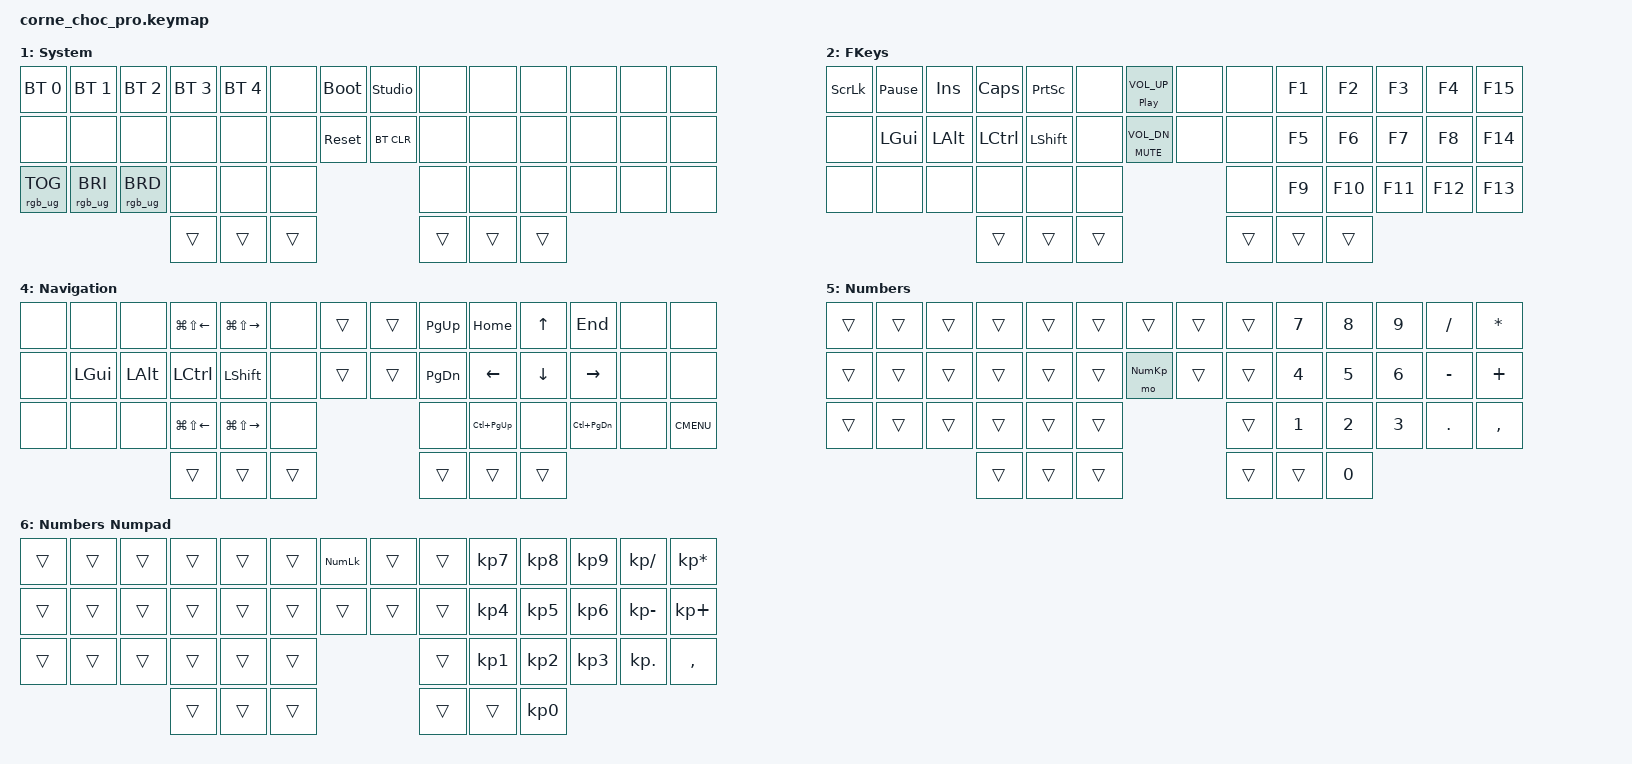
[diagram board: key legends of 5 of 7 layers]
/*
 * Copyright (c) 2020 The ZMK Contributors
 *
 * SPDX-License-Identifier: MIT
 */

#include <behaviors.dtsi>
#include <dt-bindings/zmk/keys.h>
#include <dt-bindings/zmk/bt.h>
#include <dt-bindings/zmk/rgb.h>

/ {
    chosen {
        zmk,physical-layout = &default_layout;
    };
};


/* Layers */
#define Base     0
#define Sys      1
#define FKeys    2
#define NavNum   3
#define Nav      4
#define Num      5
#define NumKp    6

#include "incl/corne_labels.h"
#include "incl/combos_lr.dtsi"
#include "incl/morphs.dtsi"
#include "incl/behaviors.dtsi"

#define __         &trans
#define xx         &none
#define PAUSEB     &kp PAUSE_BREAK

#define VOLDN_MUT  &mttl C_MUTE       C_VOL_DN
#define VOLUP_PLAY &mttl C_PLAY_PAUSE C_VOL_UP
#define BSPC_W     &mtts LC(BSPC)     BSPC
#define DEL_W      &mtts LC(DEL)      DEL

#define DESK_LEFT  &kp LG(LS(LEFT))
#define DESK_RIGHT &kp LG(LS(RIGHT))
#define DESK_PREV  &kp LG(LS(LEFT))
#define DESK_NEXT  &kp LG(LS(RIGHT))

/ {
    keymap {
        compatible = "zmk,keymap";


base_layer {  display-name = "Base";  bindings = <
// ╭──────────┬────────────┬────────────┬────────────┬─────────────┬──────────┬───────────╮╭───────────┬──────────┬──────────────┬────────────┬────────────┬────────────┬──────────╮
    &kp GRAVE  &kp B        &kp Y        &kp O        &kp U         &kp SQT    VOLUP_PLAY   BSPC_W      &min_plu   &kp L          &kp D        &kp W        &kp V        &kp Z
// ├──────────┼────────────┼────────────┼────────────┼─────────────┼──────────┼───────────┤├───────────┼──────────┼──────────────┼────────────┼────────────┼────────────┼──────────┤
    &eq_ex     HML(C,           I,           E,           A)        &com_sem   VOLDN_MUT    DEL_W       &dot_col   HMR(H,             T,           S,           N)       &kp Q
// ├──────────┼────────────┼────────────┼────────────┼─────────────┼──────────┼───────────╯╰───────────┼──────────┼──────────────┼────────────┼────────────┼────────────┼──────────┤
    xx         &kp G        &kp X        &kp J        &kp K         &q_ex                               &sl_star   &kp R          &kp M        &kp F        &kp P        &kp K_CMENU
// ╰──────────┴────────────┴────────────┼────────────┼─────────────┼──────────┤                        ├──────────┼──────────────┼────────────┼────────────┴────────────┴──────────╯
                                         &lcw Sys 0   &lt Num ESC   &kp SPACE                           &kp SPACE  &lt Nav TAB    &lcw FKeys 0
//                                      ╰────────────┴─────────────┴──────────╯                        ╰──────────┴──────────────┴────────────╯
>; };

sys_layer {  display-name = "System";  bindings = <
// ╭───────────────┬───────────────┬───────────────┬────────────┬─────────────┬──────────┬──────────╮╭──────────────┬─────────────┬─────────────┬─────────────┬─────────────┬────────────┬────────────╮
    &bt BT_SEL 0    &bt BT_SEL 1    &bt BT_SEL 2    &bt BT_SEL 3  &bt BT_SEL 4 xx         &bootloader &studio_unlock xx            xx            xx            xx            xx           xx   
// ├───────────────┼───────────────┼───────────────┼────────────┼─────────────┼──────────┼──────────┤├──────────────┼─────────────┼─────────────┼─────────────┼─────────────┼────────────┼────────────┤
    xx              xx              xx              xx           xx            xx         &sys_reset  &bt BT_CLR     xx            xx            xx            xx            xx           xx   
// ├───────────────┼───────────────┼───────────────┼────────────┼─────────────┼──────────┼──────────╯╰──────────────┼─────────────┼─────────────┼─────────────┼─────────────┼────────────┼────────────┤
    &rgb_ug RGB_TOG &rgb_ug RGB_BRI &rgb_ug RGB_BRD xx           xx            xx                                    xx            xx            xx            xx            xx           xx   
// ╰───────────────┴───────────────┴───────────────┼────────────┼─────────────┼──────────┤                          ├─────────────┴─────────────┴─────────────┴─────────────┴────────────┴────────────╯
                                                    __           __            __                                    __            __            __    
//                                                 ╰────────────┴─────────────┴──────────╯                          ╰─────────────┴─────────────┴─────────────╯
>; };

fkeys_layer {  display-name = "FKeys";  bindings = <
// ╭──────────┬──────────┬───────────┬──────────┬──────────┬──────────┬───────────╮╭──────────┬──────────┬──────────┬──────────┬──────────┬──────────┬──────────╮
    &kp SLCK   PAUSEB     &kp INS     &kp CAPS   &kp PSCRN  xx         VOLUP_PLAY   xx         xx         &kp F1     &kp F2     &kp F3     &kp F4     &kp F15
// ├──────────┼──────────┼───────────┼──────────┼──────────┼──────────┼───────────┤├──────────┼──────────┼──────────┼──────────┼──────────┼──────────┼──────────┤
    xx         &kp LGUI   &kp LALT    &kp LCTRL  &kp LSHFT  xx         VOLDN_MUT    xx         xx         &kp F5     &kp F6     &kp F7     &kp F8     &kp F14
// ├──────────┼──────────┼───────────┼──────────┼──────────┼──────────┼───────────╯╰──────────┼──────────┼──────────┼──────────┼──────────┼──────────┼──────────┤
    xx         xx         xx          xx         xx         xx                                 xx         &kp F9     &kp F10    &kp F11    &kp F12    &kp F13
// ╰──────────┴──────────┴───────────┼──────────┼──────────┼──────────┤                       ├──────────┼──────────┼──────────┼──────────┴──────────┴──────────╯
                                      __         __         __                                 __         __         __    
//                                   ╰──────────┴──────────┴──────────╯                       ╰──────────┴──────────┴──────────╯
>; };

navnum_layer {  display-name = "Nav-Num";  bindings = <
// ╭──────────┬───────────┬────────────┬───────────┬──────────────┬─────────┬──────────╮╭──────────┬──────────┬──────────┬──────────┬──────────┬───────────┬──────────╮
    &kp N0     &kp N1      &kp N2       &kp N3      &kp N4         &kp N5    __          __         __         &kp N6     &kp N7     &kp N8     &kp N9      &kp N0
// ├──────────┼───────────┼────────────┼───────────┼──────────────┼─────────┼──────────┤├──────────┼──────────┼──────────┼──────────┼──────────┼───────────┼──────────┤
    __         __          __           __          &hml LSHFT N5  __        __          __         &kp LEFT   HMR(UP,    DOWN,      RIGHT,     RIGHT)      xx   
// ├──────────┼───────────┼────────────┼───────────┼──────────────┼─────────┼──────────╯╰──────────┼──────────┼──────────┼──────────┼──────────┼───────────┼──────────┤
    __         DESK_LEFT   DESK_RIGHT   DESK_PREV   DESK_NEXT      __                               &kp HOME   &kp PG_UP  &kp PG_DN  &kp END    xx          __
// ╰──────────┴───────────┴────────────┼───────────┼──────────────┼─────────┤                      ├──────────┼──────────┼──────────┼──────────┴───────────┴──────────╯
                                        __          __             __                               __         __         __    
//                                     ╰───────────┴──────────────┴─────────╯                      ╰──────────┴──────────┴──────────╯
>; };

/* navnum_lr_layer {  display-name = "NavNum_LR";  bindings = <
// ╭──────────┬──────────┬──────────────┬───────────────┬────────────────┬─────────────┬──────────╮╭──────────┬──────────┬────────────────┬────────────────┬───────────────┬──────────┬──────────╮
    xx         xx         &kp HOME       &kp UP          &kp END          &kp PG_UP     xx          __         __         &kp KP_N7        &kp KP_N8        &kp KP_N9       xx         xx   
// ├──────────┼──────────┼──────────────┼───────────────┼────────────────┼─────────────┼──────────┤├──────────┼──────────┼────────────────┼────────────────┼───────────────┼──────────┼──────────┤
    xx         xx         &hml LALT LEFT &hml LCTRL DOWN &hml LSHFT RIGHT &kp PG_DN     xx          __         __         &hmr RSHFT KP_N4 &hmr RCTRL KP_N5 &hmr RALT KP_N6 xx         xx   
// ├──────────┼──────────┼──────────────┼───────────────┼────────────────┼─────────────┼──────────╯╰──────────┼──────────┼────────────────┼────────────────┼───────────────┼──────────┼──────────┤
    xx         xx         xx             xx              xx               xx                                   __         &kp KP_N1        &kp KP_N2        &kp KP_N3       xx         xx   
// ╰──────────┴──────────┴──────────────┼───────────────┼────────────────┼─────────────┤                      ├──────────┼────────────────┼────────────────┼───────────────┴──────────┴──────────╯
                                         __              __               __                                   __         __               &kp KP_N0
//                                      ╰───────────────┴────────────────┴─────────────╯                      ╰──────────┴────────────────┴────────────────╯
>; }; */

nav_layer {  display-name = "Navigation";  bindings = <
// ╭──────────┬──────────┬──────────┬──────────┬────────────┬────────────┬──────────╮╭──────────┬──────────┬─────────────┬─────────────┬─────────────┬──────────┬──────────╮
    xx         xx         xx         DESK_LEFT  DESK_RIGHT   xx           __          __         &kp PG_UP  &kp HOME      &kp UP        &kp END       xx         xx   
// ├──────────┼──────────┼──────────┼──────────┼────────────┼────────────┼──────────┤├──────────┼──────────┼─────────────┼─────────────┼─────────────┼──────────┼──────────┤
    xx         &kp LGUI   &kp LALT   &kp LCTRL  &kp LSHFT    xx           __          __         &kp PG_DN  &kp LEFT      &kp DOWN      &kp RIGHT     xx         xx   
// ├──────────┼──────────┼──────────┼──────────┼────────────┼────────────┼──────────╯╰──────────┼──────────┼─────────────┼─────────────┼─────────────┼──────────┼──────────┤
    xx         xx         xx         DESK_PREV  DESK_NEXT    xx                                  xx         &kp LC(PG_UP) xx            &kp LC(PG_DN) xx         &kp K_CMENU   
// ╰──────────┴──────────┴──────────┼──────────┼────────────┼────────────┤                      ├──────────┼─────────────┼─────────────┼─────────────┴──────────┴──────────╯
                                     __         __           __                                  __         __            __    
//                                  ╰──────────┴────────────┴────────────╯                      ╰──────────┴─────────────┴─────────────╯
>; };

num_layer {  display-name = "Numbers";  bindings = <
// ╭──────────┬──────────┬──────────┬──────────┬──────────┬──────────┬──────────╮╭──────────┬──────────┬──────────┬──────────┬──────────┬──────────┬──────────╮
    __         __         __         __         __         __         __          __         __         &kp N7     &kp N8     &kp N9     &kp SLASH  &kp STAR   
// ├──────────┼──────────┼──────────┼──────────┼──────────┼──────────┼──────────┤├──────────┼──────────┼──────────┼──────────┼──────────┼──────────┼──────────┤
    __         __         __         __         __         __         &mo NumKp   __         __         &kp N4     &kp N5     &kp N6     &kp MINUS  &kp PLUS   
//  __         &kp LGUI   &kp LALT   &kp LCTRL  &kp LSHFT  __         &mo NumKp   __         __         &kp N4     &kp N5     &kp N6     &kp MINUS  &kp PLUS   
// ├──────────┼──────────┼──────────┼──────────┼──────────┼──────────┼──────────╯╰──────────┼──────────┼──────────┼──────────┼──────────┼──────────┼──────────┤
    __         __         __         __         __         __                                __         &kp N1     &kp N2     &kp N3     &kp DOT    &kp COMMA
// ╰──────────┴──────────┴──────────┼──────────┼──────────┼──────────┤                      ├──────────┼──────────┼──────────┼──────────┴──────────┴──────────╯
                                     __         __         __                                __         __         &kp N0  
//                                  ╰──────────┴──────────┴──────────╯                      ╰──────────┴──────────┴──────────╯
>; };

numkp_layer {  display-name = "Numbers Numpad";  bindings = <
// ╭──────────┬──────────┬──────────┬──────────┬──────────┬──────────┬──────────╮╭──────────┬──────────┬──────────┬──────────┬──────────┬────────────┬───────────────╮
    __         __         __         __         __         __         &kp KP_NLCK __         __         &kp KP_N7  &kp KP_N8  &kp KP_N9  &kp KP_SLASH &kp KP_MULTIPLY   
// ├──────────┼──────────┼──────────┼──────────┼──────────┼──────────┼──────────┤├──────────┼──────────┼──────────┼──────────┼──────────┼────────────┼───────────────┤
    __         __         __         __         __         __         __          __         __         &kp KP_N4  &kp KP_N5  &kp KP_N6  &kp KP_MINUS &kp KP_PLUS   
//  __         &kp LGUI   &kp LALT   &kp LCTRL  &kp LSHFT  __         __          __         __         &kp KP_N4  &kp KP_N5  &kp KP_N6  &kp KP_MINUS &kp KP_PLUS   
// ├──────────┼──────────┼──────────┼──────────┼──────────┼──────────┼──────────╯╰──────────┼──────────┼──────────┼──────────┼──────────┼────────────┼───────────────┤
    __         __         __         __         __         __                                __         &kp KP_N1  &kp KP_N2  &kp KP_N3  &kp KP_DOT   &kp COMMA
// ╰──────────┴──────────┴──────────┼──────────┼──────────┼──────────┤                      ├──────────┼──────────┼──────────┼──────────┴────────────┴───────────────╯
                                     __         __         __                                __         __         &kp KP_N0  
//                                  ╰──────────┴──────────┴──────────╯                      ╰──────────┴──────────┴──────────╯
>; };

/*
none_layer {  display-name = "none";  bindings = <
// ╭──────────┬──────────┬──────────┬──────────┬──────────┬──────────┬──────────╮╭──────────┬──────────┬──────────┬──────────┬──────────┬──────────┬──────────╮
    &none      &none      &none      &none      &none      &none      &none       &none      &none      &none      &none      &none      &none      &none
// ├──────────┼──────────┼──────────┼──────────┼──────────┼──────────┼──────────┤├──────────┼──────────┼──────────┼──────────┼──────────┼──────────┼──────────┤
    &none      &none      &none      &none      &none      &none      &none       &none      &none      &none      &none      &none      &none      &none
// ├──────────┼──────────┼──────────┼──────────┼──────────┼──────────┼──────────╯╰──────────┼──────────┼──────────┼──────────┼──────────┼──────────┼──────────┤
    &none      &none      &none      &none      &none      &none                             &none      &none      &none      &none      &none      &none
// ╰──────────┴──────────┴──────────┼──────────┼──────────┼──────────┤                      ├──────────┼──────────┼──────────┼──────────┴──────────┴──────────╯
                                     &none      &none      &none                             &none      &none      &none
//                                  ╰──────────┴──────────┴──────────╯                      ╰──────────┴──────────┴──────────╯
>; };
*/
    };
};
